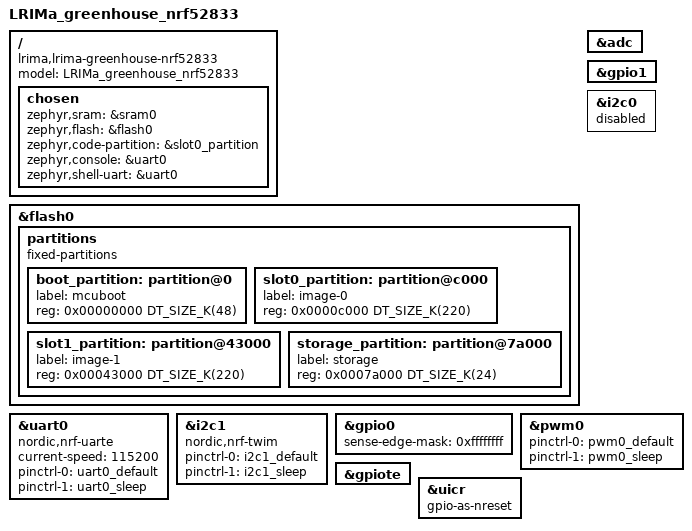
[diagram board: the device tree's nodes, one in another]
/dts-v1/;
#include <nordic/nrf52833_qiaa.dtsi>
#include "lrima_greenhouse_nrf52833-pinctrl.dtsi"

/ {
	model = "LRIMa_greenhouse_nrf52833";
	compatible = "lrima,lrima-greenhouse-nrf52833";

	chosen {
		zephyr,sram = &sram0;
		zephyr,flash = &flash0;
		zephyr,code-partition = &slot0_partition;
		zephyr,console = &uart0;
		zephyr,shell-uart = &uart0;
	};
};

&flash0 {
	partitions {
		compatible = "fixed-partitions";
		#address-cells = <1>;
		#size-cells = <1>;

		boot_partition: partition@0 {
			label = "mcuboot";
			reg = <0x00000000 DT_SIZE_K(48)>;
		};

		slot0_partition: partition@c000 {
			label = "image-0";
			reg = <0x0000c000 DT_SIZE_K(220)>;
		};

		slot1_partition: partition@43000 {
			label = "image-1";
			reg = <0x00043000 DT_SIZE_K(220)>;
		};

		storage_partition: partition@7a000 {
			label = "storage";
			reg = <0x0007a000 DT_SIZE_K(24)>;
		};
	};
};

&uart0 {
	compatible = "nordic,nrf-uarte";
	status = "okay";
	current-speed = <115200>;
	pinctrl-0 = <&uart0_default>;
	pinctrl-1 = <&uart0_sleep>;
	pinctrl-names = "default", "sleep";
};

&adc {
	status = "okay";
};

&i2c1 {
	compatible = "nordic,nrf-twim";
	/* Cannot be used together with spi1. */
	pinctrl-0 = <&i2c1_default>;
	pinctrl-1 = <&i2c1_sleep>;
	pinctrl-names = "default", "sleep";
	status = "okay";
};

&gpio0 {
	status = "okay";
	// For low-power EDGE interrupts.
	// See github.com/zephyrproject-rtos/zephyr/issues/28499.
	sense-edge-mask = <0xffffffff>;
};

&gpio1 {
	status = "okay";
};

&i2c0 { // LED1 is on P0.13 and i2c0 uses P0.13/P0.24, so disable i2c0 to avoid conflicts.
    status = "disabled";
};

&pwm0 {
	status = "okay";
	pinctrl-0 = <&pwm0_default>;
	pinctrl-1 = <&pwm0_sleep>;
	pinctrl-names = "default", "sleep";
};

&gpiote {
	status = "okay";
};

&uicr {
	gpio-as-nreset;
};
